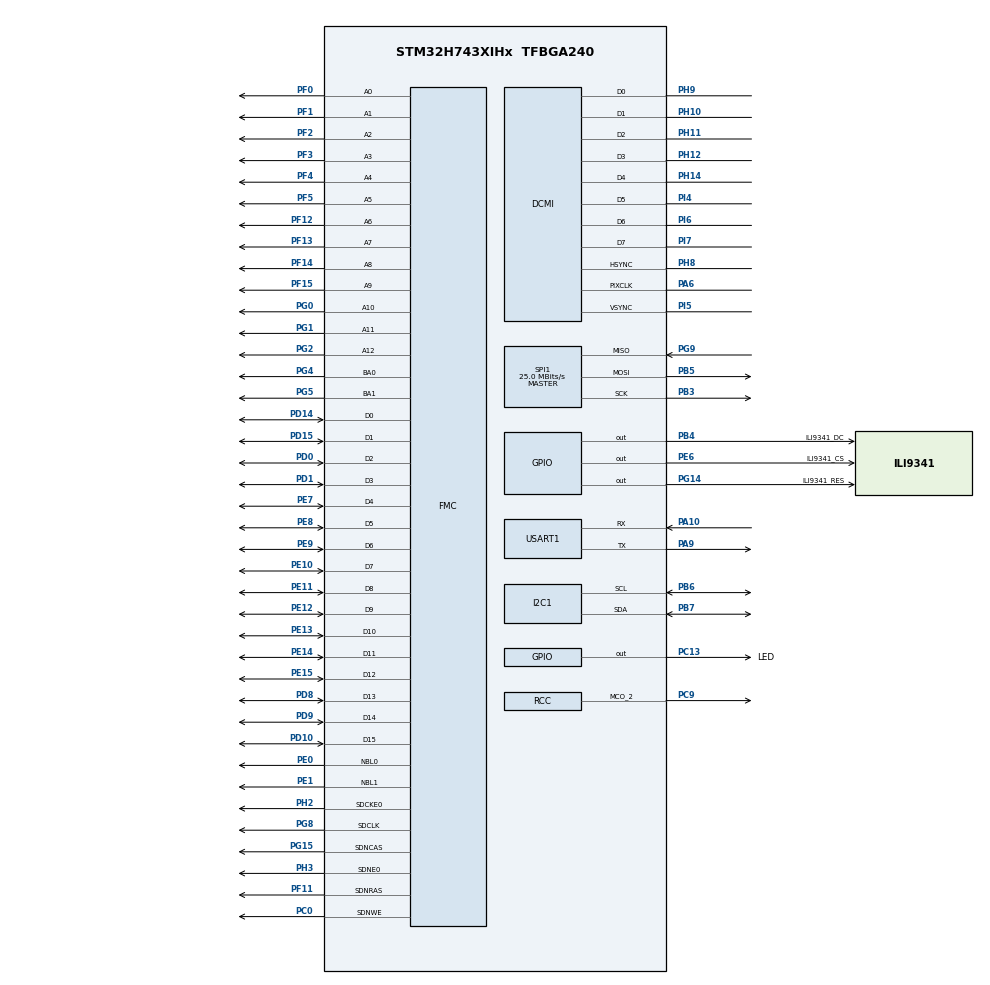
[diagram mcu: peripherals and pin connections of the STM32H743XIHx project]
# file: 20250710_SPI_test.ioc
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CORTEX_M7.AccessPermission_S-Cortex_Memory_Protection_Unit_Region4_Settings_S=MPU_REGION_FULL_ACCESS
CORTEX_M7.BaseAddress_S-Cortex_Memory_Protection_Unit_Region4_Settings_S=0xC0000000
CORTEX_M7.CPU_DCache=Enabled
CORTEX_M7.CPU_ICache=Enabled
CORTEX_M7.DisableExec_S-Cortex_Memory_Protection_Unit_Region4_Settings_S=MPU_INSTRUCTION_ACCESS_DISABLE
CORTEX_M7.Enable_S-Cortex_Memory_Protection_Unit_Region4_Settings_S=MPU_REGION_ENABLE
CORTEX_M7.IsShareable_S-Cortex_Memory_Protection_Unit_Region4_Settings_S=MPU_ACCESS_SHAREABLE
CORTEX_M7.Size_S-Cortex_Memory_Protection_Unit_Region4_Settings_S=MPU_REGION_SIZE_32MB
CORTEX_M7.TypeExtField_S-Cortex_Memory_Protection_Unit_Region4_Settings_S=MPU_TEX_LEVEL1
CORTEX_M7.default_mode_Activation=1
DCMI.JPEGMode=DCMI_JPEG_DISABLE
DCMI.PCKPolarity=DCMI_PCKPOLARITY_RISING
DCMI.VSPolarity=DCMI_VSPOLARITY_HIGH
Dma.DCMI.1.Direction=DMA_PERIPH_TO_MEMORY
Dma.DCMI.1.EventEnable=DISABLE
Dma.DCMI.1.FIFOMode=DMA_FIFOMODE_DISABLE
Dma.DCMI.1.Instance=DMA1_Stream1
Dma.DCMI.1.MemDataAlignment=DMA_MDATAALIGN_WORD
Dma.DCMI.1.MemInc=DMA_MINC_ENABLE
Dma.DCMI.1.Mode=DMA_NORMAL
Dma.DCMI.1.PeriphDataAlignment=DMA_PDATAALIGN_WORD
Dma.DCMI.1.PeriphInc=DMA_PINC_DISABLE
Dma.DCMI.1.Polarity=HAL_DMAMUX_REQ_GEN_RISING
Dma.DCMI.1.Priority=DMA_PRIORITY_LOW
Dma.DCMI.1.RequestNumber=1
Dma.DCMI.1.SignalID=NONE
Dma.DCMI.1.SyncEnable=DISABLE
Dma.DCMI.1.SyncPolarity=HAL_DMAMUX_SYNC_NO_EVENT
Dma.DCMI.1.SyncRequestNumber=1
Dma.DCMI.1.SyncSignalID=NONE
Dma.Request0=SPI1_TX
Dma.Request1=DCMI
Dma.SPI1_TX.0.Direction=DMA_MEMORY_TO_PERIPH
Dma.SPI1_TX.0.EventEnable=DISABLE
Dma.SPI1_TX.0.FIFOMode=DMA_FIFOMODE_DISABLE
Dma.SPI1_TX.0.Instance=DMA1_Stream0
Dma.SPI1_TX.0.MemDataAlignment=DMA_MDATAALIGN_BYTE
Dma.SPI1_TX.0.MemInc=DMA_MINC_ENABLE
Dma.SPI1_TX.0.Mode=DMA_NORMAL
Dma.SPI1_TX.0.PeriphDataAlignment=DMA_PDATAALIGN_BYTE
Dma.SPI1_TX.0.PeriphInc=DMA_PINC_DISABLE
Dma.SPI1_TX.0.Polarity=HAL_DMAMUX_REQ_GEN_RISING
Dma.SPI1_TX.0.Priority=DMA_PRIORITY_LOW
Dma.SPI1_TX.0.RequestNumber=1
Dma.SPI1_TX.0.SignalID=NONE
Dma.SPI1_TX.0.SyncEnable=DISABLE
Dma.SPI1_TX.0.SyncPolarity=HAL_DMAMUX_SYNC_NO_EVENT
Dma.SPI1_TX.0.SyncRequestNumber=1
Dma.SPI1_TX.0.SyncSignalID=NONE
FMC.CASLatency1=FMC_SDRAM_CAS_LATENCY_2
FMC.ColumnBitsNumber1=FMC_SDRAM_COLUMN_BITS_NUM_9
FMC.ExitSelfRefreshDelay1=9
FMC.LoadToActiveDelay1=2
FMC.RCDDelay1=3
FMC.RPDelay1=3
FMC.RowCycleDelay1=8
FMC.SDClockPeriod1=FMC_SDRAM_CLOCK_PERIOD_2
FMC.SelfRefreshTime1=6
FMC.WriteRecoveryTime1=3
I2C1.Timing=0x307075B1
Mcu.Family=STM32H7
Mcu.Name=STM32H743XIHx
Mcu.Package=TFBGA240
NVIC.DCMI_IRQn=true\:0\:0\:false\:false\:true\:true\:true\:true
NVIC.DMA1_Stream0_IRQn=true\:0\:0\:false\:false\:true\:false\:true\:true
NVIC.DMA1_Stream1_IRQn=true\:0\:0\:false\:false\:true\:false\:true\:true
NVIC.PriorityGroup=NVIC_PRIORITYGROUP_4
NVIC.SPI1_IRQn=true\:0\:0\:false\:false\:true\:false\:true\:true
PA10.Mode=Asynchronous
PA10.Signal=USART1_RX
PA13\ (JTMS/SWDIO).Mode=Serial_Wire
PA13\ (JTMS/SWDIO).Signal=DEBUG_JTMS-SWDIO
PA14\ (JTCK/SWCLK).Mode=Serial_Wire
PA14\ (JTCK/SWCLK).Signal=DEBUG_JTCK-SWCLK
PA6.Mode=Slave_8_bits_External_Synchro
PA6.Signal=DCMI_PIXCLK
PA9.Mode=Asynchronous
PA9.Signal=USART1_TX
PB3\ (JTDO/TRACESWO).Mode=Full_Duplex_Master
PB3\ (JTDO/TRACESWO).Signal=SPI1_SCK
PB4\ (NJTRST).GPIO_Label=ILI9341_DC
PB4\ (NJTRST).Signal=GPIO_Output
PB5.Mode=Full_Duplex_Master
PB5.Signal=SPI1_MOSI
PB6.Mode=I2C
PB6.Signal=I2C1_SCL
PB7.Mode=I2C
PB7.Signal=I2C1_SDA
PC0.Signal=FMC_SDNWE
PC13.GPIO_Label=LED
PC13.Signal=GPIO_Output
PC9.Mode=Clock-out-2
PC9.Signal=RCC_MCO_2
PD0.Signal=FMC_D2_DA2
PD1.Signal=FMC_D3_DA3
PD10.Signal=FMC_D15_DA15
PD14.Signal=FMC_D0_DA0
PD15.Signal=FMC_D1_DA1
PD8.Signal=FMC_D13_DA13
PD9.Signal=FMC_D14_DA14
PE0.Signal=FMC_NBL0
PE1.Signal=FMC_NBL1
PE10.Signal=FMC_D7_DA7
PE11.Signal=FMC_D8_DA8
PE12.Signal=FMC_D9_DA9
PE13.Signal=FMC_D10_DA10
PE14.Signal=FMC_D11_DA11
PE15.Signal=FMC_D12_DA12
PE6.GPIO_Label=ILI9341_CS
PE6.Signal=GPIO_Output
PE7.Signal=FMC_D4_DA4
PE8.Signal=FMC_D5_DA5
PE9.Signal=FMC_D6_DA6
PF0.Signal=FMC_A0
PF1.Signal=FMC_A1
PF11.Signal=FMC_SDNRAS
PF12.Signal=FMC_A6
PF13.Signal=FMC_A7
PF14.Signal=FMC_A8
PF15.Signal=FMC_A9
PF2.Signal=FMC_A2
PF3.Signal=FMC_A3
PF4.Signal=FMC_A4
PF5.Signal=FMC_A5
PG0.Signal=FMC_A10
PG1.Signal=FMC_A11
PG14.GPIO_Label=ILI9341_RES
PG14.Signal=GPIO_Output
PG15.Signal=FMC_SDNCAS
PG2.Signal=FMC_A12
PG4.Signal=FMC_A14_BA0
PG5.Signal=FMC_A15_BA1
PG8.Signal=FMC_SDCLK
PG9.Mode=Full_Duplex_Master
PG9.Signal=SPI1_MISO
PH0-OSC_IN\ (PH0).Mode=HSE-External-Oscillator
PH0-OSC_IN\ (PH0).Signal=RCC_OSC_IN
PH1-OSC_OUT\ (PH1).Mode=HSE-External-Oscillator
PH1-OSC_OUT\ (PH1).Signal=RCC_OSC_OUT
PH10.Mode=Slave_8_bits_External_Synchro
PH10.Signal=DCMI_D1
PH11.Mode=Slave_8_bits_External_Synchro
PH11.Signal=DCMI_D2
PH12.Mode=Slave_8_bits_External_Synchro
PH12.Signal=DCMI_D3
PH14.Mode=Slave_8_bits_External_Synchro
PH14.Signal=DCMI_D4
PH2.Mode=SdramChipSelect1_1
PH2.Signal=FMC_SDCKE0
PH3.Mode=SdramChipSelect1_1
PH3.Signal=FMC_SDNE0
PH8.Mode=Slave_8_bits_External_Synchro
PH8.Signal=DCMI_HSYNC
PH9.Mode=Slave_8_bits_External_Synchro
PH9.Signal=DCMI_D0
PI4.Mode=Slave_8_bits_External_Synchro
PI4.Signal=DCMI_D5
PI5.Mode=Slave_8_bits_External_Synchro
PI5.Signal=DCMI_VSYNC
PI6.Mode=Slave_8_bits_External_Synchro
PI6.Signal=DCMI_D6
PI7.Mode=Slave_8_bits_External_Synchro
PI7.Signal=DCMI_D7
ProjectManager.HeapSize=0x200
ProjectManager.StackSize=0x400
ProjectManager.TargetToolchain=STM32CubeIDE
RCC.ADCFreq_Value=96000000
RCC.APB1Freq_Value=120000000
RCC.APB2Freq_Value=120000000
RCC.APB3Freq_Value=120000000
RCC.APB4Freq_Value=120000000
RCC.CortexFreq_Value=480000000
RCC.D1PPRE=RCC_APB3_DIV2
RCC.D2PPRE1=RCC_APB1_DIV2
RCC.D2PPRE2=RCC_APB2_DIV2
RCC.D3PPRE=RCC_APB4_DIV2
RCC.DIVM1=5
RCC.DIVM2=25
RCC.DIVM3=25
RCC.DIVN1=192
RCC.DIVN2=192
RCC.DIVN3=200
RCC.HCLKFreq_Value=240000000
RCC.HPRE=RCC_HCLK_DIV2
RCC.PLLFRACN=0
RCC.PLLSourceVirtual=RCC_PLLSOURCE_HSE
RCC.RCC_MCO2Source=RCC_MCO2SOURCE_PLL2PCLK
RCC.RCC_MCODiv2=RCC_MCODIV_8
RCC.SPI123CLockSelection=RCC_SPI123CLKSOURCE_PLL3
RCC.SYSCLKFreq_VALUE=480000000
RCC.SYSCLKSource=RCC_SYSCLKSOURCE_PLLCLK
RCC.USBFreq_Value=480000000
SH.FMC_A0.0=FMC_A0,13b-sda1
SH.FMC_A1.0=FMC_A1,13b-sda1
SH.FMC_A10.0=FMC_A10,13b-sda1
SH.FMC_A11.0=FMC_A11,13b-sda1
SH.FMC_A12.0=FMC_A12,13b-sda1
SH.FMC_A14_BA0.0=FMC_BA0,FourSdramBanks1
SH.FMC_A15_BA1.0=FMC_BA1,FourSdramBanks1
SH.FMC_A2.0=FMC_A2,13b-sda1
SH.FMC_A3.0=FMC_A3,13b-sda1
SH.FMC_A4.0=FMC_A4,13b-sda1
SH.FMC_A5.0=FMC_A5,13b-sda1
SH.FMC_A6.0=FMC_A6,13b-sda1
SH.FMC_A7.0=FMC_A7,13b-sda1
SH.FMC_A8.0=FMC_A8,13b-sda1
SH.FMC_A9.0=FMC_A9,13b-sda1
SH.FMC_D0_DA0.0=FMC_D0,sd-16b-d1
SH.FMC_D10_DA10.0=FMC_D10,sd-16b-d1
SH.FMC_D11_DA11.0=FMC_D11,sd-16b-d1
SH.FMC_D12_DA12.0=FMC_D12,sd-16b-d1
SH.FMC_D13_DA13.0=FMC_D13,sd-16b-d1
SH.FMC_D14_DA14.0=FMC_D14,sd-16b-d1
SH.FMC_D15_DA15.0=FMC_D15,sd-16b-d1
SH.FMC_D1_DA1.0=FMC_D1,sd-16b-d1
SH.FMC_D2_DA2.0=FMC_D2,sd-16b-d1
SH.FMC_D3_DA3.0=FMC_D3,sd-16b-d1
SH.FMC_D4_DA4.0=FMC_D4,sd-16b-d1
SH.FMC_D5_DA5.0=FMC_D5,sd-16b-d1
SH.FMC_D6_DA6.0=FMC_D6,sd-16b-d1
SH.FMC_D7_DA7.0=FMC_D7,sd-16b-d1
SH.FMC_D8_DA8.0=FMC_D8,sd-16b-d1
SH.FMC_D9_DA9.0=FMC_D9,sd-16b-d1
SH.FMC_NBL0.0=FMC_NBL0,Sd2ByteEnable1
SH.FMC_NBL1.0=FMC_NBL1,Sd2ByteEnable1
SH.FMC_SDCLK.0=FMC_SDCLK,13b-sda1
SH.FMC_SDNCAS.0=FMC_SDNCAS,13b-sda1
SH.FMC_SDNRAS.0=FMC_SDNRAS,13b-sda1
SH.FMC_SDNWE.0=FMC_SDNWE,13b-sda1
SPI1.BaudRatePrescaler=SPI_BAUDRATEPRESCALER_4
SPI1.CalculateBaudRate=25.0 MBits/s
SPI1.DataSize=SPI_DATASIZE_8BIT
SPI1.Direction=SPI_DIRECTION_2LINES
SPI1.Mode=SPI_MODE_MASTER
SPI1.NSSPMode=SPI_NSS_PULSE_DISABLE
SPI1.VirtualType=VM_MASTER
USART1.VirtualMode-Asynchronous=VM_ASYNC
VP_MEMORYMAP_VS_MEMORYMAP.Mode=CurAppReg
board=custom

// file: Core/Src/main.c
/* USER CODE BEGIN Header */
/**
 ******************************************************************************
 * @file           : main.c
 * @brief          : Main program body
 ******************************************************************************
 * @attention
 *
 * Copyright (c) 2025 STMicroelectronics.
 * All rights reserved.
 *
 * This software is licensed under terms that can be found in the LICENSE file
 * in the root directory of this software component.
 * If no LICENSE file comes with this software, it is provided AS-IS.
 *
 ******************************************************************************
 */
/* USER CODE END Header */
#include "main.h"
#include "dcmi.h"
#include "dma.h"
#include "i2c.h"
#include "memorymap.h"
#include "spi.h"
#include "usart.h"
#include "gpio.h"
#include "fmc.h"

/* USER CODE BEGIN PV */
int __io_putchar(int ch)
{

	HAL_UART_Transmit(&huart1, (uint8_t *)&ch, 1, 1000);

	return ch;
}
/* USER CODE END PV */

void SystemClock_Config(void);
void PeriphCommonClock_Config(void);
static void MPU_Config(void);

int main(void)
{

  /* MPU Configuration--------------------------------------------------------*/
  MPU_Config();

  /* Enable the CPU Cache */

  /* Enable I-Cache---------------------------------------------------------*/
  SCB_EnableICache();

  /* Enable D-Cache---------------------------------------------------------*/
  SCB_EnableDCache();

  /* MCU Configuration--------------------------------------------------------*/

  /* Reset of all peripherals, Initializes the Flash interface and the Systick. */
  HAL_Init();

  /* Configure the system clock */
  SystemClock_Config();

  /* Configure the peripherals common clocks */
  PeriphCommonClock_Config();

  /* Initialize all configured peripherals */
  MX_GPIO_Init();
  MX_DMA_Init();
  MX_SPI1_Init();
  MX_USART1_UART_Init();
  MX_FMC_Init();
  MX_DCMI_Init();
  MX_I2C1_Init();
  /* USER CODE BEGIN 2 */

	printf("hello world\n");

  /* USER CODE END 2 */

  /* Infinite loop */
	while (1)
	{

	}
}

void SystemClock_Config(void)
{
  RCC_OscInitTypeDef RCC_OscInitStruct = {0};
  RCC_ClkInitTypeDef RCC_ClkInitStruct = {0};

  /** Supply configuration update enable
  */
  HAL_PWREx_ConfigSupply(PWR_LDO_SUPPLY);

  /** Configure the main internal regulator output voltage
  */
  __HAL_PWR_VOLTAGESCALING_CONFIG(PWR_REGULATOR_VOLTAGE_SCALE0);

  while(!__HAL_PWR_GET_FLAG(PWR_FLAG_VOSRDY)) {}

  /** Initializes the RCC Oscillators according to the specified parameters
  * in the RCC_OscInitTypeDef structure.
  */
  RCC_OscInitStruct.OscillatorType = RCC_OSCILLATORTYPE_HSE;
  RCC_OscInitStruct.HSEState = RCC_HSE_ON;
  RCC_OscInitStruct.PLL.PLLState = RCC_PLL_ON;
  RCC_OscInitStruct.PLL.PLLSource = RCC_PLLSOURCE_HSE;
  RCC_OscInitStruct.PLL.PLLM = 5;
  RCC_OscInitStruct.PLL.PLLN = 192;
  RCC_OscInitStruct.PLL.PLLP = 2;
  RCC_OscInitStruct.PLL.PLLQ = 2;
  RCC_OscInitStruct.PLL.PLLR = 2;
  RCC_OscInitStruct.PLL.PLLRGE = RCC_PLL1VCIRANGE_2;
  RCC_OscInitStruct.PLL.PLLVCOSEL = RCC_PLL1VCOWIDE;
  RCC_OscInitStruct.PLL.PLLFRACN = 0;
  if (HAL_RCC_OscConfig(&RCC_OscInitStruct) != HAL_OK)
  {
    Error_Handler();
  }

  /** Initializes the CPU, AHB and APB buses clocks
  */
  RCC_ClkInitStruct.ClockType = RCC_CLOCKTYPE_HCLK|RCC_CLOCKTYPE_SYSCLK
                              |RCC_CLOCKTYPE_PCLK1|RCC_CLOCKTYPE_PCLK2
                              |RCC_CLOCKTYPE_D3PCLK1|RCC_CLOCKTYPE_D1PCLK1;
  RCC_ClkInitStruct.SYSCLKSource = RCC_SYSCLKSOURCE_PLLCLK;
  RCC_ClkInitStruct.SYSCLKDivider = RCC_SYSCLK_DIV1;
  RCC_ClkInitStruct.AHBCLKDivider = RCC_HCLK_DIV2;
  RCC_ClkInitStruct.APB3CLKDivider = RCC_APB3_DIV2;
  RCC_ClkInitStruct.APB1CLKDivider = RCC_APB1_DIV2;
  RCC_ClkInitStruct.APB2CLKDivider = RCC_APB2_DIV2;
  RCC_ClkInitStruct.APB4CLKDivider = RCC_APB4_DIV2;

  if (HAL_RCC_ClockConfig(&RCC_ClkInitStruct, FLASH_LATENCY_4) != HAL_OK)
  {
    Error_Handler();
  }
  __HAL_RCC_PLL2CLKOUT_ENABLE(RCC_PLL2_DIVP);
  HAL_RCC_MCOConfig(RCC_MCO2, RCC_MCO2SOURCE_PLL2PCLK, RCC_MCODIV_8);
}

void PeriphCommonClock_Config(void)
{

  /** Enables PLL2P clock output
  */
  __HAL_RCC_PLL2_CONFIG(25, 192, 2, 2, 2);
  __HAL_RCC_PLL2_VCIRANGE(RCC_PLL2VCIRANGE_0);
  __HAL_RCC_PLL2_VCORANGE(RCC_PLL2VCOWIDE);
  __HAL_RCC_PLL2_ENABLE();
}

 /* MPU Configuration */

void MPU_Config(void)
{
  MPU_Region_InitTypeDef MPU_InitStruct = {0};

  /* Disables the MPU */
  HAL_MPU_Disable();

  /** Initializes and configures the Region and the memory to be protected
  */
  MPU_InitStruct.Enable = MPU_REGION_ENABLE;
  MPU_InitStruct.Number = MPU_REGION_NUMBER0;
  MPU_InitStruct.BaseAddress = 0x0;
  MPU_InitStruct.Size = MPU_REGION_SIZE_4GB;
  MPU_InitStruct.SubRegionDisable = 0x87;
  MPU_InitStruct.TypeExtField = MPU_TEX_LEVEL0;
  MPU_InitStruct.AccessPermission = MPU_REGION_NO_ACCESS;
  MPU_InitStruct.DisableExec = MPU_INSTRUCTION_ACCESS_DISABLE;
  MPU_InitStruct.IsShareable = MPU_ACCESS_SHAREABLE;
  MPU_InitStruct.IsCacheable = MPU_ACCESS_NOT_CACHEABLE;
  MPU_InitStruct.IsBufferable = MPU_ACCESS_NOT_BUFFERABLE;

  HAL_MPU_ConfigRegion(&MPU_InitStruct);

  /** Initializes and configures the Region and the memory to be protected
  */
  MPU_InitStruct.Number = MPU_REGION_NUMBER4;
  MPU_InitStruct.BaseAddress = 0xC0000000;
  MPU_InitStruct.Size = MPU_REGION_SIZE_32MB;
  MPU_InitStruct.SubRegionDisable = 0x0;
  MPU_InitStruct.TypeExtField = MPU_TEX_LEVEL1;
  MPU_InitStruct.AccessPermission = MPU_REGION_FULL_ACCESS;

  HAL_MPU_ConfigRegion(&MPU_InitStruct);
  /* Enables the MPU */
  HAL_MPU_Enable(MPU_PRIVILEGED_DEFAULT);

}

void Error_Handler(void)
{
	__disable_irq();
	while (1)
	{
	}
}
